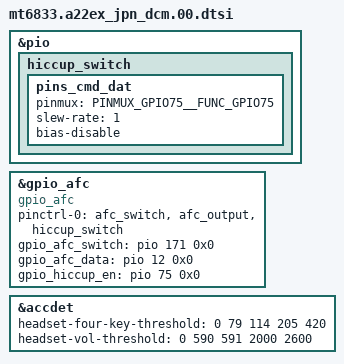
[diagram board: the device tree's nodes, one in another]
/* 
 * Generated by Samsung 
 * If these files should be changed, then please make a sync with MTK
*/

#include "mt6833-a22ex_common.dtsi"
#include "mt6833_input_a22ex_common.dtsi"
#include "mt6833-a22ex_camera_00.dtsi"

&pio {
	hiccup_switch: hiccup_switch {
		pins_cmd_dat {
			pinmux = <PINMUX_GPIO75__FUNC_GPIO75>;
			slew-rate = <1>;
			bias-disable;
		};
	};
};

&gpio_afc {
	compatible = "gpio_afc";
	pinctrl-names = "default";
	pinctrl-0 = <&afc_switch &afc_output &hiccup_switch>;
	status = "okay";
	gpio_afc_switch = <&pio 171 0x0>;
	gpio_afc_data = <&pio 12 0x0>;
	gpio_hiccup_en = <&pio 75 0x0>;
};

&accdet {
	headset-four-key-threshold = <0 79 114 205 420>;
	headset-vol-threshold = <0 590 591 2000 2600>;
};

/*End of this file, DO NOT ADD ANYTHING HERE*/
